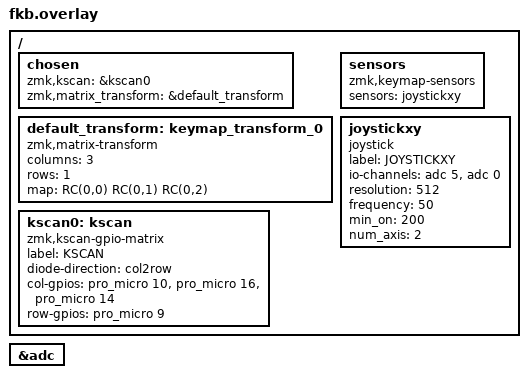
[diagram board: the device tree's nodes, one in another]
#include <dt-bindings/zmk/matrix_transform.h>

/ {
    chosen {
        zmk,kscan = &kscan0;
		zmk,matrix_transform = &default_transform;
    };

    default_transform: keymap_transform_0 {
		compatible = "zmk,matrix-transform";
		columns = <3>;
		rows = <1>;
		map = <
RC(0,0) RC(0,1) RC(0,2)
	  >;
	};

    kscan0: kscan {
        compatible = "zmk,kscan-gpio-matrix";
        label = "KSCAN";

        diode-direction = "col2row";
        col-gpios
            = <&pro_micro 10 GPIO_ACTIVE_HIGH>
            , <&pro_micro 16 GPIO_ACTIVE_HIGH>
            , <&pro_micro 14 GPIO_ACTIVE_HIGH>
            ;

       row-gpios
           = <&pro_micro 9 (GPIO_ACTIVE_HIGH | GPIO_PULL_DOWN)>
           ;
    };
	
   sensors {
        compatible = "zmk,keymap-sensors";
        sensors = <&joystickxy>;
    };

    joystickxy: joystickxy {
        compatible = "joystick";
        label = "JOYSTICKXY";
	io-channels = <&adc 5 &adc 0>;
	status = "okay";
	resolution = <512>;
	frequency = <50>;
	min_on = <200>;
	num_axis = <2>;
    };
};

&adc {
	status = "okay";
};
